# NUC123AE_v1 register map
File version: 1.0
Registers are 32-bit, read-write, reset 0x0 unless marked. A register's access mark holds for its fields unless they carry their own. Offsets are from the block's base; [hi:lo] are bit positions; {n}, {i} and the like mark numbered series; 'fields as' and 'values as' point back to an identical list.

## GP (part 2 of 2) — GP Register Map
Base 0x50004000
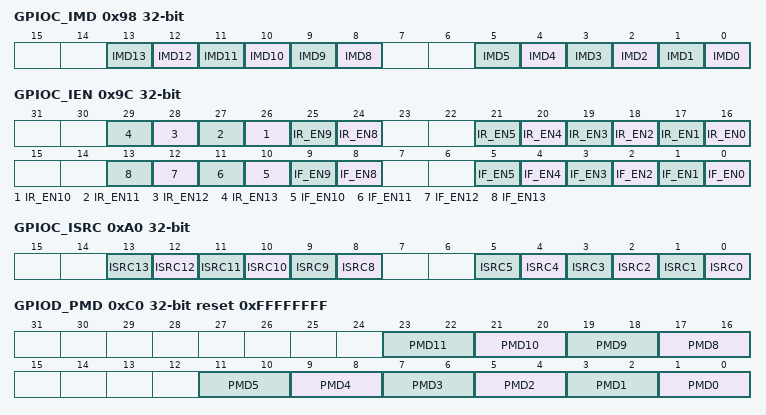
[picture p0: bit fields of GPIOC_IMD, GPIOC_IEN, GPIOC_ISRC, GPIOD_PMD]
0x98 GPIOC_IMD — GPIO Port C Interrupt Mode Control
  [all] fields
    0=Edge trigger interrupt; 1=Level trigger interrupt
  [n] IMD{n} (n=8..13) — Port [A/B/C/D/ F] Edge or Level Detection Interrupt Control. IMD[n] is used to control the interrupt is by level trigger or by edge trigger. If the interrupt is by edge trigger, the trigger source can be controlled by de-bounce. If the interrupt is by level trigger, the input source is sampled by one HCLK clock and generates the interrupt. If pin is set as the level trigger interrupt, only one level can be set on the registers GPIOx_IEN. If set both the level to trigger interrupt, the setting is ignored and no interrupt will occur. The de-bounce function is valid for edge triggered interrupt. If the interrupt mode is level triggered, the de-bounce enable bit is ignored. Note: GPIOA: Valid n are 15~10. Others are reserved. GPIOB: Valid n are 15~12, 10~0. Others are reserved. GPIOC: Valid n are 13~8, 5~0. Others are reserved. GPIOD: Valid n are 11~8, 5~0. Others are reserved. GPIOF: Valid n are 3~0. Others are reserved.
  [n] IMD{n} (n=0..5) — Port [A/B/C/D/ F] Edge or Level Detection Interrupt Control. IMD[n] is used to control the interrupt is by level trigger or by edge trigger. If the interrupt is by edge trigger, the trigger source can be controlled by de-bounce. If the interrupt is by level trigger, the input source is sampled by one HCLK clock and generates the interrupt. If pin is set as the level trigger interrupt, only one level can be set on the registers GPIOx_IEN. If set both the level to trigger interrupt, the setting is ignored and no interrupt will occur. The de-bounce function is valid for edge triggered interrupt. If the interrupt mode is level triggered, the de-bounce enable bit is ignored. Note: GPIOA: Valid n are 15~10. Others are reserved. GPIOB: Valid n are 15~12, 10~0. Others are reserved. GPIOC: Valid n are 13~8, 5~0. Others are reserved. GPIOD: Valid n are 11~8, 5~0. Others are reserved. GPIOF: Valid n are 3~0. Others are reserved.
0x9C GPIOC_IEN — GPIO Port C Interrupt Enable
  [n+16] IR_EN{n} (n=8..13) — Port [A/B/C/D/ F] Interrupt Enable by Input Rising Edge or Input Level High. IR_EN[n] is used to enable the interrupt for each of the corresponding input GPIO_PIN[n]. Set bit to 1 also enable the pin wake-up function. When the IR_EN[n] bit is set to 1: If the interrupt is level triggered, the input PIN[n] state at level "high" will generate the interrupt. If the interrupt is edge triggered, the input PIN[n] state changes from "low-to-high" will generate the interrupt. Note: GPIOA: Valid n are 15~10. Others are reserved. GPIOB: Valid n are 15~12, 10~0. Others are reserved. GPIOC: Valid n are 13~8, 5~0. Others are reserved. GPIOD: Valid n are 11~8, 5~0. Others are reserved. GPIOF: Valid n are 3~0. Others are reserved.
    0=PIN[n] level-high or low-to-high interrupt Disabled; 1=PIN[n] level-high or low-to-high interrupt Enabled
  [n+16] IR_EN{n} (n=0..5) — Port [A/B/C/D/ F] Interrupt Enable by Input Rising Edge or Input Level High. IR_EN[n] is used to enable the interrupt for each of the corresponding input GPIO_PIN[n]. Set bit to 1 also enable the pin wake-up function. When the IR_EN[n] bit is set to 1: If the interrupt is level triggered, the input PIN[n] state at level "high" will generate the interrupt. If the interrupt is edge triggered, the input PIN[n] state changes from "low-to-high" will generate the interrupt. Note: GPIOA: Valid n are 15~10. Others are reserved. GPIOB: Valid n are 15~12, 10~0. Others are reserved. GPIOC: Valid n are 13~8, 5~0. Others are reserved. GPIOD: Valid n are 11~8, 5~0. Others are reserved. GPIOF: Valid n are 3~0. Others are reserved.
    values as IR_EN8
  [n] IF_EN{n} (n=8..13) — Port [A/B/C/D/ F] Interrupt Enable by Input Falling Edge or Input Level Low. IF_EN[n] is used to enable the interrupt for each of the corresponding input GPIO_PIN[n]. Set bit to 1 also enable the pin wake-up function. When set the IF_EN[n] bit to 1: If the interrupt is level triggered, the input PIN[n] state at level "low" will generate the interrupt. If the interrupt is edge triggered, the input PIN[n] state changes from "high-to-low" will generate the interrupt. Note: GPIOA: Valid n are 15~10. Others are reserved. GPIOB: Valid n are 15~12, 10~0. Others are reserved. GPIOC: Valid n are 13~8, 5~0. Others are reserved. GPIOD: Valid n are 11~8, 5~0. Others are reserved. GPIOF: Valid n are 3~0. Others are reserved.
    0=PIN[n] state low-level or high-to-low change interrupt Disabled; 1=PIN[n] state low-level or high-to-low change interrupt Enabled
  [n] IF_EN{n} (n=0..5) — Port [A/B/C/D/ F] Interrupt Enable by Input Falling Edge or Input Level Low. IF_EN[n] is used to enable the interrupt for each of the corresponding input GPIO_PIN[n]. Set bit to 1 also enable the pin wake-up function. When set the IF_EN[n] bit to 1: If the interrupt is level triggered, the input PIN[n] state at level "low" will generate the interrupt. If the interrupt is edge triggered, the input PIN[n] state changes from "high-to-low" will generate the interrupt. Note: GPIOA: Valid n are 15~10. Others are reserved. GPIOB: Valid n are 15~12, 10~0. Others are reserved. GPIOC: Valid n are 13~8, 5~0. Others are reserved. GPIOD: Valid n are 11~8, 5~0. Others are reserved. GPIOF: Valid n are 3~0. Others are reserved.
    values as IF_EN8
0xA0 GPIOC_ISRC — GPIO Port C Interrupt Trigger Source Indicator
  [all] fields
    0=No interrupt at GPIOx[n]. No action; 1=Indicates GPIOx[n] generate an interrupt. Clear the corresponding pending interrupt
  [n] ISRC{n} (n=8..13) — Port [A/B/C/D/ F] Interrupt Trigger Source Indicator. Read: Note: GPIOA: Valid n are 15~10. Others are reserved. GPIOB: Valid n are 15~12, 10~0. Others are reserved. GPIOC: Valid n are 13~8, 5~0. Others are reserved. GPIOD: Valid n are 11~8, 5~0. Others are reserved. GPIOF: Valid n are 3~0. Others are reserved.
  [n] ISRC{n} (n=0..5) — Port [A/B/C/D/ F] Interrupt Trigger Source Indicator. Read: Note: GPIOA: Valid n are 15~10. Others are reserved. GPIOB: Valid n are 15~12, 10~0. Others are reserved. GPIOC: Valid n are 13~8, 5~0. Others are reserved. GPIOD: Valid n are 11~8, 5~0. Others are reserved. GPIOF: Valid n are 3~0. Others are reserved.
0xC0 GPIOD_PMD reset 0xFFFFFFFF — GPIO Port D Pin I/O Mode Control
  [all] fields
    0=GPIO port [n] pin is in INPUT mode; 1=GPIO port [n] pin is in OUTPUT mode; 2=GPIO port [n] pin is in Open-Drain mode; 3=GPIO port [n] pin is in Quasi-bidirectional mode
  [2n+1:2n] PMD{n} (n=8..11) — GPIOx I/O Pin[n] Mode Control. Determine each I/O type of GPIOx pins. Note: GPIOA: valid n are 15~10. Others are reserved. GPIOB: valid n are 15~12, 10~0. Others are reserved. GPIOC: valid n are 13~8, 5~0. Others are reserved. GPIOD: valid n are 11~8, 5~0. Others are reserved. GPIOF: valid n are 3~0. Others are reserved.
  [2n+1:2n] PMD{n} (n=0..5) — GPIOx I/O Pin[n] Mode Control. Determine each I/O type of GPIOx pins. Note: GPIOA: valid n are 15~10. Others are reserved. GPIOB: valid n are 15~12, 10~0. Others are reserved. GPIOC: valid n are 13~8, 5~0. Others are reserved. GPIOD: valid n are 11~8, 5~0. Others are reserved. GPIOF: valid n are 3~0. Others are reserved.
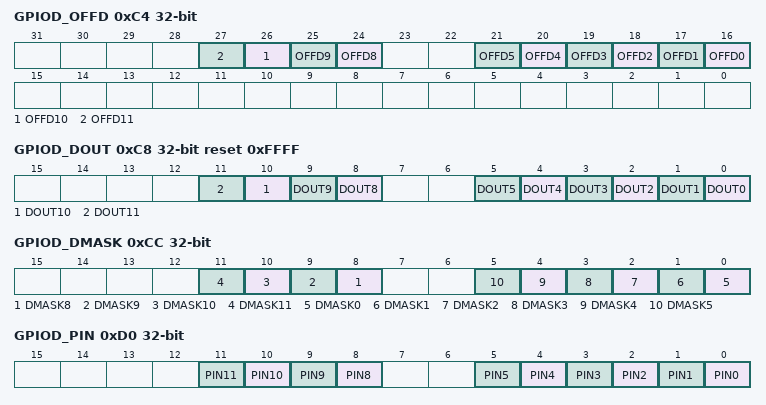
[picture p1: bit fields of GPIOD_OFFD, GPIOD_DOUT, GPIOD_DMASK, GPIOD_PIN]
0xC4 GPIOD_OFFD — GPIO Port D Pin OFF Digital Enable
  [all] fields
    0=IO digital input path Enabled; 1=IO digital input path Disabled (digital input tied to low)
  [n+16] OFFD{n} (n=8..11) — GPIOx Pin[n] OFF Digital Input Path Enable. Each of these bits is used to control if the input path of corresponding GPIO pin is disabled. If input is analog signal, user can OFF digital input path to avoid creepage. Notes: GPIOA: valid n are 15~10. Others are reserved. GPIOB: valid n are 15~12, 10~0. Others are reserved. GPIOC: valid n are 13~8, 5~0. Others are reserved. GPIOD: valid n are 11~8, 5~0. Others are reserved. GPIOF: valid n are 3~0. Others are reserved.
  [n+16] OFFD{n} (n=0..5) — GPIOx Pin[n] OFF Digital Input Path Enable. Each of these bits is used to control if the input path of corresponding GPIO pin is disabled. If input is analog signal, user can OFF digital input path to avoid creepage. Notes: GPIOA: valid n are 15~10. Others are reserved. GPIOB: valid n are 15~12, 10~0. Others are reserved. GPIOC: valid n are 13~8, 5~0. Others are reserved. GPIOD: valid n are 11~8, 5~0. Others are reserved. GPIOF: valid n are 3~0. Others are reserved.
0xC8 GPIOD_DOUT reset 0xFFFF — GPIO Port D Data Output Value
  [all] fields
    0=GPIO port [A/B/C/D/ F] Pin[n] will drive Low if the GPIO pin is configures as output, open-drain and quasi-mode; 1=GPIO port [A/B/C/DF] Pin[n] will drive High if the GPIO pin is configures as output, open-drain and quasi-mode
  [n] DOUT{n} (n=8..11) — GPIOx Pin[n] Output Value. Each of these bits control the status of a GPIO pin when the GPIO pin is configures as output, open-drain and quasi-mode. Note: GPIOA: valid n are 15~10. Others are reserved. GPIOB: valid n are 15~12, 10~0. Others are reserved. GPIOC: valid n are 13~8, 5~0. Others are reserved. GPIOD: valid n are 11~8, 5~0. Others are reserved. GPIOF: valid n are 3~0. Others are reserved.
  [n] DOUT{n} (n=0..5) — GPIOx Pin[n] Output Value. Each of these bits control the status of a GPIO pin when the GPIO pin is configures as output, open-drain and quasi-mode. Note: GPIOA: valid n are 15~10. Others are reserved. GPIOB: valid n are 15~12, 10~0. Others are reserved. GPIOC: valid n are 13~8, 5~0. Others are reserved. GPIOD: valid n are 11~8, 5~0. Others are reserved. GPIOF: valid n are 3~0. Others are reserved.
0xCC GPIOD_DMASK — GPIO Port D Data Output Write Mask
  [all] fields
    0=The corresponding GPIOx_DOUT[n] bit can be updated; 1=The corresponding GPIOx_DOUT[n] bit is protected
  [n] DMASK{n} (n=8..11) — Port [A/B/C/D/ F] Data Output Write Mask. These bits are used to protect the corresponding register of GPIOx_DOUT bit[n]. When set the DMASK bit[n] to 1, the corresponding GPIOx_DOUT[n] bit is protected. The write signal is masked, write data to the protect bit is ignored. Note: This function only protect corresponding GPIOx_DOUT[n] bit, and will not protect corresponding bit control register (GPIOAx_DOUT, GPIOBx_DOUT, GPIOCx_DOUT, GPIODx_DOUT and GPIOFx_DOUT). Note: GPIOA: valid n are 15~10. Others are reserved. GPIOB: valid n are 15~12, 10~0. Others are reserved. GPIOC: valid n are 13~8, 5~0. Others are reserved. GPIOD: valid n are 11~8, 5~0. Others are reserved. GPIOF: valid n are 3~0. Others are reserved.
  [n] DMASK{n} (n=0..5) — Port [A/B/C/D/ F] Data Output Write Mask. These bits are used to protect the corresponding register of GPIOx_DOUT bit[n]. When set the DMASK bit[n] to 1, the corresponding GPIOx_DOUT[n] bit is protected. The write signal is masked, write data to the protect bit is ignored. Note: This function only protect corresponding GPIOx_DOUT[n] bit, and will not protect corresponding bit control register (GPIOAx_DOUT, GPIOBx_DOUT, GPIOCx_DOUT, GPIODx_DOUT and GPIOFx_DOUT). Note: GPIOA: valid n are 15~10. Others are reserved. GPIOB: valid n are 15~12, 10~0. Others are reserved. GPIOC: valid n are 13~8, 5~0. Others are reserved. GPIOD: valid n are 11~8, 5~0. Others are reserved. GPIOF: valid n are 3~0. Others are reserved.
0xD0 GPIOD_PIN ro (reset mask 0xFFFF0000) — GPIO Port D Pin Value
  [n] PIN{n} (n=8..11) — Port [A/B/C/D/ F] Pin Values. Each bit of the register reflects the actual status of the respective GPIO pin If bit is 1, it indicates the corresponding pin status is high, else the pin status is low. Note: GPIOA: valid n are 15~10. Others are reserved. GPIOB: valid n are 15~12, 10~0. Others are reserved. GPIOC: valid n are 13~8, 5~0. Others are reserved. GPIOD: valid n are 11~8, 5~0. Others are reserved. GPIOF: valid n are 3~0. Others are reserved.
  [n] PIN{n} (n=0..5) — Port [A/B/C/D/ F] Pin Values. Each bit of the register reflects the actual status of the respective GPIO pin If bit is 1, it indicates the corresponding pin status is high, else the pin status is low. Note: GPIOA: valid n are 15~10. Others are reserved. GPIOB: valid n are 15~12, 10~0. Others are reserved. GPIOC: valid n are 13~8, 5~0. Others are reserved. GPIOD: valid n are 11~8, 5~0. Others are reserved. GPIOF: valid n are 3~0. Others are reserved.
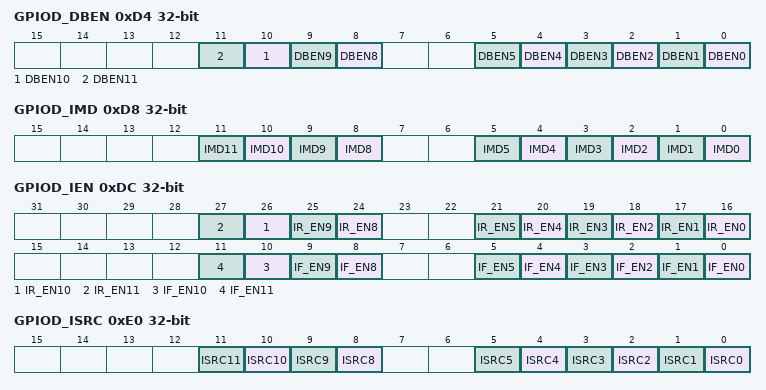
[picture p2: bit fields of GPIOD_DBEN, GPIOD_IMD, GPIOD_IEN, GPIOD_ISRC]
0xD4 GPIOD_DBEN — GPIO Port D De-bounce Enable
  [all] fields
    0=The bit[n] de-bounce function is disabled; 1=The bit[n] de-bounce function is enabled
  [n] DBEN{n} (n=8..11) — Port [A/B/C/D/ F] Input Signal De-bounce Enable. DBEN[n]used to enable the de-bounce function for each corresponding bit. If the input signal pulse width can't be sampled by continuous two de-bounce sample cycle The input signal transition is seen as the signal bounce and will not trigger the interrupt. The de-bounce clock source is controlled by DBNCECON[4], one de-bounce sample cycle is controlled by DBNCECON[3:0]. The DBEN[n] is used for "edge-trigger" interrupt only, and ignored for "level trigger" interrupt. The de-bounce function is valid for edge triggered interrupt. If the interrupt mode is level triggered, the de-bounce enable bit is ignored. Note: GPIOA: valid n are 15~10. Others are reserved. GPIOB: valid n are 15~12, 10~0. Others are reserved. GPIOC: valid n are 13~8, 5~0. Others are reserved. GPIOD: valid n are 11~8, 5~0. Others are reserved. GPIOF: valid n are 3~0. Others are reserved.
  [n] DBEN{n} (n=0..5) — Port [A/B/C/D/ F] Input Signal De-bounce Enable. DBEN[n]used to enable the de-bounce function for each corresponding bit. If the input signal pulse width can't be sampled by continuous two de-bounce sample cycle The input signal transition is seen as the signal bounce and will not trigger the interrupt. The de-bounce clock source is controlled by DBNCECON[4], one de-bounce sample cycle is controlled by DBNCECON[3:0]. The DBEN[n] is used for "edge-trigger" interrupt only, and ignored for "level trigger" interrupt. The de-bounce function is valid for edge triggered interrupt. If the interrupt mode is level triggered, the de-bounce enable bit is ignored. Note: GPIOA: valid n are 15~10. Others are reserved. GPIOB: valid n are 15~12, 10~0. Others are reserved. GPIOC: valid n are 13~8, 5~0. Others are reserved. GPIOD: valid n are 11~8, 5~0. Others are reserved. GPIOF: valid n are 3~0. Others are reserved.
0xD8 GPIOD_IMD — GPIO Port D Interrupt Mode Control
  [all] fields
    0=Edge trigger interrupt; 1=Level trigger interrupt
  [n] IMD{n} (n=8..11) — Port [A/B/C/D/ F] Edge or Level Detection Interrupt Control. IMD[n] is used to control the interrupt is by level trigger or by edge trigger. If the interrupt is by edge trigger, the trigger source can be controlled by de-bounce. If the interrupt is by level trigger, the input source is sampled by one HCLK clock and generates the interrupt. If pin is set as the level trigger interrupt, only one level can be set on the registers GPIOx_IEN. If set both the level to trigger interrupt, the setting is ignored and no interrupt will occur. The de-bounce function is valid for edge triggered interrupt. If the interrupt mode is level triggered, the de-bounce enable bit is ignored. Note: GPIOA: Valid n are 15~10. Others are reserved. GPIOB: Valid n are 15~12, 10~0. Others are reserved. GPIOC: Valid n are 13~8, 5~0. Others are reserved. GPIOD: Valid n are 11~8, 5~0. Others are reserved. GPIOF: Valid n are 3~0. Others are reserved.
  [n] IMD{n} (n=0..5) — Port [A/B/C/D/ F] Edge or Level Detection Interrupt Control. IMD[n] is used to control the interrupt is by level trigger or by edge trigger. If the interrupt is by edge trigger, the trigger source can be controlled by de-bounce. If the interrupt is by level trigger, the input source is sampled by one HCLK clock and generates the interrupt. If pin is set as the level trigger interrupt, only one level can be set on the registers GPIOx_IEN. If set both the level to trigger interrupt, the setting is ignored and no interrupt will occur. The de-bounce function is valid for edge triggered interrupt. If the interrupt mode is level triggered, the de-bounce enable bit is ignored. Note: GPIOA: Valid n are 15~10. Others are reserved. GPIOB: Valid n are 15~12, 10~0. Others are reserved. GPIOC: Valid n are 13~8, 5~0. Others are reserved. GPIOD: Valid n are 11~8, 5~0. Others are reserved. GPIOF: Valid n are 3~0. Others are reserved.
0xDC GPIOD_IEN — GPIO Port D Interrupt Enable
  [n+16] IR_EN{n} (n=8..11) — Port [A/B/C/D/ F] Interrupt Enable by Input Rising Edge or Input Level High. IR_EN[n] is used to enable the interrupt for each of the corresponding input GPIO_PIN[n]. Set bit to 1 also enable the pin wake-up function. When the IR_EN[n] bit is set to 1: If the interrupt is level triggered, the input PIN[n] state at level "high" will generate the interrupt. If the interrupt is edge triggered, the input PIN[n] state changes from "low-to-high" will generate the interrupt. Note: GPIOA: Valid n are 15~10. Others are reserved. GPIOB: Valid n are 15~12, 10~0. Others are reserved. GPIOC: Valid n are 13~8, 5~0. Others are reserved. GPIOD: Valid n are 11~8, 5~0. Others are reserved. GPIOF: Valid n are 3~0. Others are reserved.
    values as GPIOC_IEN.IR_EN8
  [n+16] IR_EN{n} (n=0..5) — Port [A/B/C/D/ F] Interrupt Enable by Input Rising Edge or Input Level High. IR_EN[n] is used to enable the interrupt for each of the corresponding input GPIO_PIN[n]. Set bit to 1 also enable the pin wake-up function. When the IR_EN[n] bit is set to 1: If the interrupt is level triggered, the input PIN[n] state at level "high" will generate the interrupt. If the interrupt is edge triggered, the input PIN[n] state changes from "low-to-high" will generate the interrupt. Note: GPIOA: Valid n are 15~10. Others are reserved. GPIOB: Valid n are 15~12, 10~0. Others are reserved. GPIOC: Valid n are 13~8, 5~0. Others are reserved. GPIOD: Valid n are 11~8, 5~0. Others are reserved. GPIOF: Valid n are 3~0. Others are reserved.
    values as GPIOC_IEN.IR_EN8
  [n] IF_EN{n} (n=8..11) — Port [A/B/C/D/ F] Interrupt Enable by Input Falling Edge or Input Level Low. IF_EN[n] is used to enable the interrupt for each of the corresponding input GPIO_PIN[n]. Set bit to 1 also enable the pin wake-up function. When set the IF_EN[n] bit to 1: If the interrupt is level triggered, the input PIN[n] state at level "low" will generate the interrupt. If the interrupt is edge triggered, the input PIN[n] state changes from "high-to-low" will generate the interrupt. Note: GPIOA: Valid n are 15~10. Others are reserved. GPIOB: Valid n are 15~12, 10~0. Others are reserved. GPIOC: Valid n are 13~8, 5~0. Others are reserved. GPIOD: Valid n are 11~8, 5~0. Others are reserved. GPIOF: Valid n are 3~0. Others are reserved.
    values as GPIOC_IEN.IF_EN8
  [n] IF_EN{n} (n=0..5) — Port [A/B/C/D/ F] Interrupt Enable by Input Falling Edge or Input Level Low. IF_EN[n] is used to enable the interrupt for each of the corresponding input GPIO_PIN[n]. Set bit to 1 also enable the pin wake-up function. When set the IF_EN[n] bit to 1: If the interrupt is level triggered, the input PIN[n] state at level "low" will generate the interrupt. If the interrupt is edge triggered, the input PIN[n] state changes from "high-to-low" will generate the interrupt. Note: GPIOA: Valid n are 15~10. Others are reserved. GPIOB: Valid n are 15~12, 10~0. Others are reserved. GPIOC: Valid n are 13~8, 5~0. Others are reserved. GPIOD: Valid n are 11~8, 5~0. Others are reserved. GPIOF: Valid n are 3~0. Others are reserved.
    values as GPIOC_IEN.IF_EN8
0xE0 GPIOD_ISRC — GPIO Port D Interrupt Trigger Source Indicator
  [all] fields
    values as the fields of GPIOC_ISRC
  [n] ISRC{n} (n=8..11) — Port [A/B/C/D/ F] Interrupt Trigger Source Indicator. Read: Note: GPIOA: Valid n are 15~10. Others are reserved. GPIOB: Valid n are 15~12, 10~0. Others are reserved. GPIOC: Valid n are 13~8, 5~0. Others are reserved. GPIOD: Valid n are 11~8, 5~0. Others are reserved. GPIOF: Valid n are 3~0. Others are reserved.
  [n] ISRC{n} (n=0..5) — Port [A/B/C/D/ F] Interrupt Trigger Source Indicator. Read: Note: GPIOA: Valid n are 15~10. Others are reserved. GPIOB: Valid n are 15~12, 10~0. Others are reserved. GPIOC: Valid n are 13~8, 5~0. Others are reserved. GPIOD: Valid n are 11~8, 5~0. Others are reserved. GPIOF: Valid n are 3~0. Others are reserved.
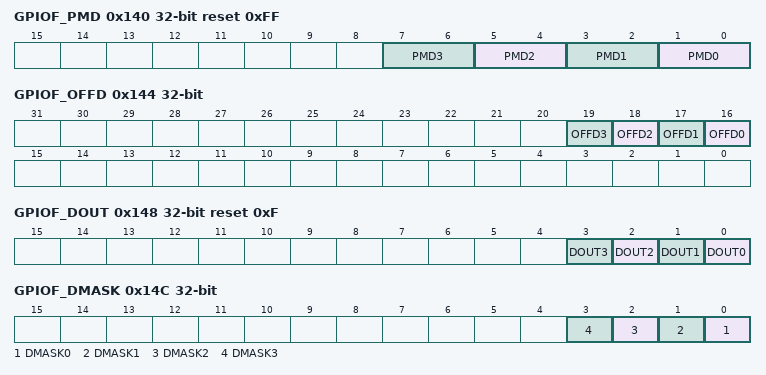
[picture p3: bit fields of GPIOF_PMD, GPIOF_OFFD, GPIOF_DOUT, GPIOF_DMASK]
0x140 GPIOF_PMD reset 0xFF — GPIO Port F Pin I/O Mode Control
  [all] fields
    values as the fields of GPIOD_PMD
  [2n+1:2n] PMD{n} (n=0..3) — GPIOx I/O Pin[n] Mode Control. Determine each I/O type of GPIOx pins. Note: GPIOA: valid n are 15~10. Others are reserved. GPIOB: valid n are 15~12, 10~0. Others are reserved. GPIOC: valid n are 13~8, 5~0. Others are reserved. GPIOD: valid n are 11~8, 5~0. Others are reserved. GPIOF: valid n are 3~0. Others are reserved.
0x144 GPIOF_OFFD — GPIO Port F Pin OFF Digital Enable
  [all] fields
    values as the fields of GPIOD_OFFD
  [n+16] OFFD{n} (n=0..3) — GPIOx Pin[n] OFF Digital Input Path Enable. Each of these bits is used to control if the input path of corresponding GPIO pin is disabled. If input is analog signal, user can OFF digital input path to avoid creepage. Notes: GPIOA: valid n are 15~10. Others are reserved. GPIOB: valid n are 15~12, 10~0. Others are reserved. GPIOC: valid n are 13~8, 5~0. Others are reserved. GPIOD: valid n are 11~8, 5~0. Others are reserved. GPIOF: valid n are 3~0. Others are reserved.
0x148 GPIOF_DOUT reset 0xF — GPIO Port F Data Output Value
  [all] fields
    values as the fields of GPIOD_DOUT
  [n] DOUT{n} (n=0..3) — GPIOx Pin[n] Output Value. Each of these bits control the status of a GPIO pin when the GPIO pin is configures as output, open-drain and quasi-mode. Note: GPIOA: valid n are 15~10. Others are reserved. GPIOB: valid n are 15~12, 10~0. Others are reserved. GPIOC: valid n are 13~8, 5~0. Others are reserved. GPIOD: valid n are 11~8, 5~0. Others are reserved. GPIOF: valid n are 3~0. Others are reserved.
0x14C GPIOF_DMASK — GPIO Port F Data Output Write Mask
  [all] fields
    values as the fields of GPIOD_DMASK
  [n] DMASK{n} (n=0..3) — Port [A/B/C/D/ F] Data Output Write Mask. These bits are used to protect the corresponding register of GPIOx_DOUT bit[n]. When set the DMASK bit[n] to 1, the corresponding GPIOx_DOUT[n] bit is protected. The write signal is masked, write data to the protect bit is ignored. Note: This function only protect corresponding GPIOx_DOUT[n] bit, and will not protect corresponding bit control register (GPIOAx_DOUT, GPIOBx_DOUT, GPIOCx_DOUT, GPIODx_DOUT and GPIOFx_DOUT). Note: GPIOA: valid n are 15~10. Others are reserved. GPIOB: valid n are 15~12, 10~0. Others are reserved. GPIOC: valid n are 13~8, 5~0. Others are reserved. GPIOD: valid n are 11~8, 5~0. Others are reserved. GPIOF: valid n are 3~0. Others are reserved.
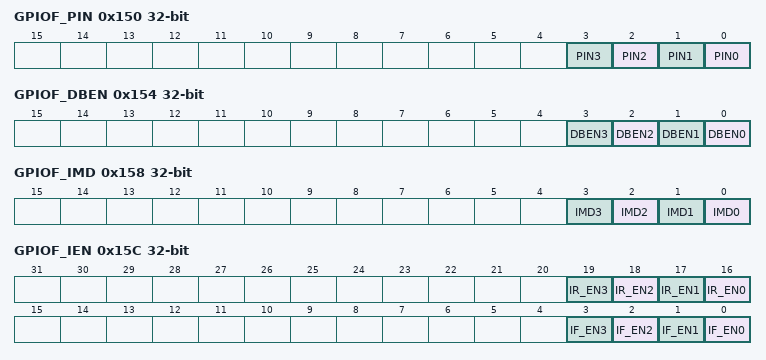
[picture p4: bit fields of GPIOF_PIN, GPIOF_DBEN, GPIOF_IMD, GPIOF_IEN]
0x150 GPIOF_PIN ro (reset mask 0xFFFFFFF0) — GPIO Port F Pin Value
  [n] PIN{n} (n=0..3) — Port [A/B/C/D/ F] Pin Values. Each bit of the register reflects the actual status of the respective GPIO pin If bit is 1, it indicates the corresponding pin status is high, else the pin status is low. Note: GPIOA: valid n are 15~10. Others are reserved. GPIOB: valid n are 15~12, 10~0. Others are reserved. GPIOC: valid n are 13~8, 5~0. Others are reserved. GPIOD: valid n are 11~8, 5~0. Others are reserved. GPIOF: valid n are 3~0. Others are reserved.
0x154 GPIOF_DBEN — GPIO Port F De-bounce Enable
  [all] fields
    values as the fields of GPIOD_DBEN
  [n] DBEN{n} (n=0..3) — Port [A/B/C/D/ F] Input Signal De-bounce Enable. DBEN[n]used to enable the de-bounce function for each corresponding bit. If the input signal pulse width can't be sampled by continuous two de-bounce sample cycle The input signal transition is seen as the signal bounce and will not trigger the interrupt. The de-bounce clock source is controlled by DBNCECON[4], one de-bounce sample cycle is controlled by DBNCECON[3:0]. The DBEN[n] is used for "edge-trigger" interrupt only, and ignored for "level trigger" interrupt. The de-bounce function is valid for edge triggered interrupt. If the interrupt mode is level triggered, the de-bounce enable bit is ignored. Note: GPIOA: valid n are 15~10. Others are reserved. GPIOB: valid n are 15~12, 10~0. Others are reserved. GPIOC: valid n are 13~8, 5~0. Others are reserved. GPIOD: valid n are 11~8, 5~0. Others are reserved. GPIOF: valid n are 3~0. Others are reserved.
0x158 GPIOF_IMD — GPIO Port F Interrupt Mode Control
  [all] fields
    0=Edge trigger interrupt; 1=Level trigger interrupt
  [n] IMD{n} (n=0..3) — Port [A/B/C/D/ F] Edge or Level Detection Interrupt Control. IMD[n] is used to control the interrupt is by level trigger or by edge trigger. If the interrupt is by edge trigger, the trigger source can be controlled by de-bounce. If the interrupt is by level trigger, the input source is sampled by one HCLK clock and generates the interrupt. If pin is set as the level trigger interrupt, only one level can be set on the registers GPIOx_IEN. If set both the level to trigger interrupt, the setting is ignored and no interrupt will occur. The de-bounce function is valid for edge triggered interrupt. If the interrupt mode is level triggered, the de-bounce enable bit is ignored. Note: GPIOA: Valid n are 15~10. Others are reserved. GPIOB: Valid n are 15~12, 10~0. Others are reserved. GPIOC: Valid n are 13~8, 5~0. Others are reserved. GPIOD: Valid n are 11~8, 5~0. Others are reserved. GPIOF: Valid n are 3~0. Others are reserved.
0x15C GPIOF_IEN — GPIO Port F Interrupt Enable
  [n+16] IR_EN{n} (n=0..3) — Port [A/B/C/D/ F] Interrupt Enable by Input Rising Edge or Input Level High. IR_EN[n] is used to enable the interrupt for each of the corresponding input GPIO_PIN[n]. Set bit to 1 also enable the pin wake-up function. When the IR_EN[n] bit is set to 1: If the interrupt is level triggered, the input PIN[n] state at level "high" will generate the interrupt. If the interrupt is edge triggered, the input PIN[n] state changes from "low-to-high" will generate the interrupt. Note: GPIOA: Valid n are 15~10. Others are reserved. GPIOB: Valid n are 15~12, 10~0. Others are reserved. GPIOC: Valid n are 13~8, 5~0. Others are reserved. GPIOD: Valid n are 11~8, 5~0. Others are reserved. GPIOF: Valid n are 3~0. Others are reserved.
    values as GPIOC_IEN.IR_EN8
  [n] IF_EN{n} (n=0..3) — Port [A/B/C/D/ F] Interrupt Enable by Input Falling Edge or Input Level Low. IF_EN[n] is used to enable the interrupt for each of the corresponding input GPIO_PIN[n]. Set bit to 1 also enable the pin wake-up function. When set the IF_EN[n] bit to 1: If the interrupt is level triggered, the input PIN[n] state at level "low" will generate the interrupt. If the interrupt is edge triggered, the input PIN[n] state changes from "high-to-low" will generate the interrupt. Note: GPIOA: Valid n are 15~10. Others are reserved. GPIOB: Valid n are 15~12, 10~0. Others are reserved. GPIOC: Valid n are 13~8, 5~0. Others are reserved. GPIOD: Valid n are 11~8, 5~0. Others are reserved. GPIOF: Valid n are 3~0. Others are reserved.
    values as GPIOC_IEN.IF_EN8
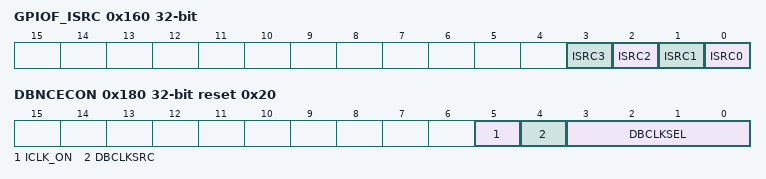
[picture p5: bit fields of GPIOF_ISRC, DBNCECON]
0x160 GPIOF_ISRC — GPIO Port F Interrupt Trigger Source Indicator
  [all] fields
    values as the fields of GPIOC_ISRC
  [n] ISRC{n} (n=0..3) — Port [A/B/C/D/ F] Interrupt Trigger Source Indicator. Read: Note: GPIOA: Valid n are 15~10. Others are reserved. GPIOB: Valid n are 15~12, 10~0. Others are reserved. GPIOC: Valid n are 13~8, 5~0. Others are reserved. GPIOD: Valid n are 11~8, 5~0. Others are reserved. GPIOF: Valid n are 3~0. Others are reserved.
0x180 DBNCECON reset 0x20 — De-bounce Cycle Control
  [5] ICLK_ON — Interrupt clock On mode. Setting this bit to 0 will disable the interrupt generate circuit clock if the pin[n] interrupt is disabled
    0=Clock Disabled if the GPIOA/B/C/D/F[n] interrupt is disabled; 1=Interrupt generated circuit clock always Enabled
  [4] DBCLKSRC — De-bounce counter clock source select
    0=De-bounce counter clock source is the HCLK; 1=De-bounce counter clock source is the internal 10 kHz low speed oscillator
  [3:0] DBCLKSEL — De-bounce sampling cycle selection
{0x200+4i} GPIOA{i}_DOUT reset 0x1 (i=10..15) — GPIO Port A Pin I/O Bit Output/Input Control
  [0] GPIOxx_DOUT — GPIOxx I/O Pin Bit Output/Input Control. Writing this bit can control one GPIO pin output value. Read this register to get IO pin status. For example: Writing GPIOA0_DOUT will reflect the written value to bit GPIOA_DOUT[0], read GPIOA0_DOUT will return the value of GPIOA_PIN[0]
    0=Set the corresponding GPIO pin to low; 1=Set the corresponding GPIO pin to high
0x240 GPIOB0_DOUT reset 0x1 — GPIO Port A Pin I/O Bit Output/Input Control
  fields as GPIOA10_DOUT
{0x240+4i} GPIOB{i}_DOUT reset 0x1 (i=1..15) — GPIO Port B Pin I/O Bit Output/Input Control
  fields as GPIOA10_DOUT
{0x280+4i} GPIOC{i}_DOUT reset 0x1 (i=0..13) — GPIO Port C Pin I/O Bit Output/Input Control
  fields as GPIOA10_DOUT
{0x2C0+4i} GPIOD{i}_DOUT reset 0x1 (i=0..11) — GPIO Port D Pin I/O Bit Output/Input Control
  fields as GPIOA10_DOUT
{0x340+4i} GPIOF{i}_DOUT reset 0x1 (i=0..3) — GPIO Port F Pin I/O Bit Output/Input Control
  fields as GPIOA10_DOUT
